# RP2040 register map
Vendor: Raspberry Pi; Series: RP; File version: 0.1
CPU: CM0PLUS r0p1, little endian, MPU, no FPU, VTOR, 2 interrupt priority bits, 32 interrupts
Registers are 32-bit, read-write, reset 0x0 unless marked. A register's access mark holds for its fields unless they carry their own. Offsets are from the block's base; [hi:lo] are bit positions; {n}, {i} and the like mark numbered series; 'fields as' and 'values as' point back to an identical list.

## PWM — Simple PWM
Base 0x40050000
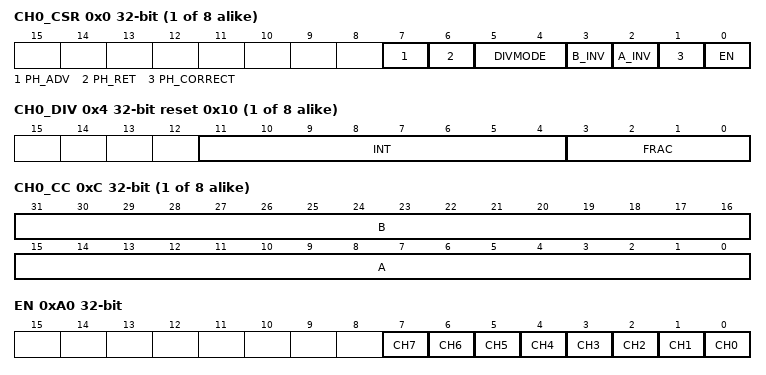
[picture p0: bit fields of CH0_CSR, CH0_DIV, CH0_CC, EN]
{0x0+0x14*i} CH{i}_CSR (i=0..7) — Control and status register
  [7] PH_ADV write-1-clears — Advance the phase of the counter by 1 count, while it is running. Self-clearing. Write a 1, and poll until low. Counter must be running at less than full speed (div_int + div_frac / 16 > 1)
  [6] PH_RET write-1-clears — Retard the phase of the counter by 1 count, while it is running. Self-clearing. Write a 1, and poll until low. Counter must be running.
  [5:4] DIVMODE
    0=div (Free-running counting at rate dictated by fractional divider); 1=level (Fractional divider operation is gated by the PWM B pin.); 2=rise (Counter advances with each rising edge of the PWM B pin.); 3=fall (Counter advances with each falling edge of the PWM B pin.)
  [3] B_INV — Invert output B
  [2] A_INV — Invert output A
  [1] PH_CORRECT — 1: Enable phase-correct modulation. 0: Trailing-edge
  [0] EN — Enable the PWM channel.
{0x4+0x14*i} CH{i}_DIV reset 0x10 (i=0..7) — INT and FRAC form a fixed-point fractional number. Counting rate is system clock frequency divided by this number. Fractional division uses simple 1st-order sigma-delta.
  [11:4] INT, [3:0] FRAC
{0x8+0x14*i} CH{i}_CTR (i=0..7) — Direct access to the PWM counter
  [15:0] CH{i}_CTR
{0xC+0x14*i} CH{i}_CC (i=0..7) — Counter compare values
  [31:16] B, [15:0] A
{0x10+0x14*i} CH{i}_TOP reset 0xFFFF (i=0..7) — Counter wrap value
  [15:0] CH{i}_TOP
0xA0 EN — This register aliases the CSR_EN bits for all channels. Writing to this register allows multiple channels to be enabled or disabled simultaneously, so they can run in perfect sync. For each channel, there is only one physical EN register bit, which can be accessed through here or CHx_CSR.
  [n] CH{n} (n=0..7)
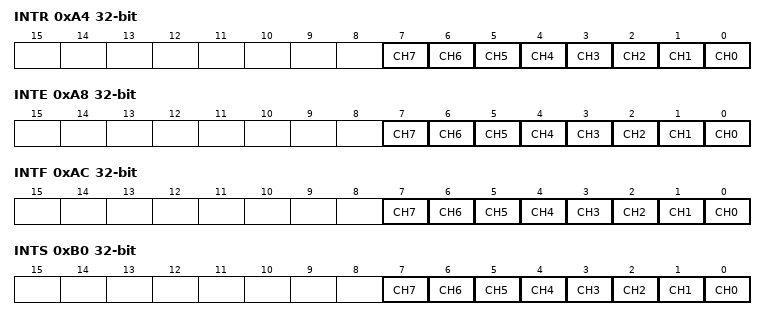
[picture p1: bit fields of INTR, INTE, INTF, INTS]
0xA4 INTR — Raw Interrupts
  [n] CH{n} write-1-clears (n=0..7)
0xA8 INTE — Interrupt Enable
  [n] CH{n} (n=0..7)
0xAC INTF — Interrupt Force
  [n] CH{n} (n=0..7)
0xB0 INTS — Interrupt status after masking & forcing
  [n] CH{n} ro (n=0..7)

## RESETS
Base 0x4000C000
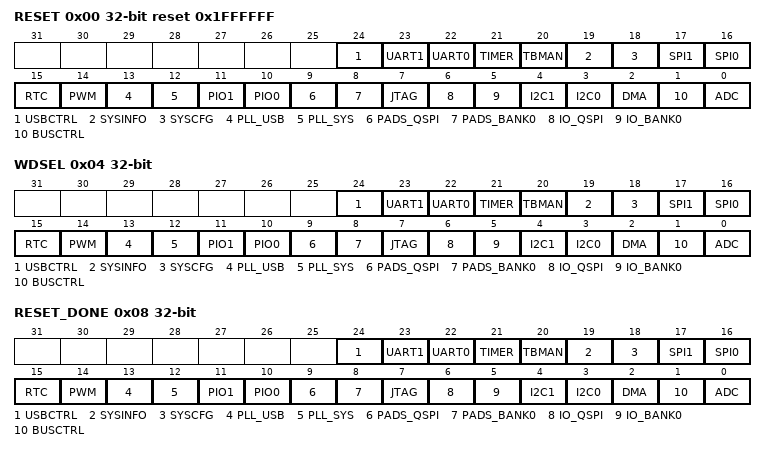
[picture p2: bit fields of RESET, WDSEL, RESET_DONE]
0x00 RESET reset 0x1FFFFFF — Reset control. If a bit is set it means the peripheral is in reset. 0 means the peripheral's reset is deasserted.
  [24] USBCTRL, [23] UART1, [22] UART0, [21] TIMER, [20] TBMAN, [19] SYSINFO, [18] SYSCFG, [17] SPI1, [16] SPI0, [15] RTC, [14] PWM, [13] PLL_USB, [12] PLL_SYS, [11] PIO1, [10] PIO0, [9] PADS_QSPI, [8] PADS_BANK0, [7] JTAG, [6] IO_QSPI, [5] IO_BANK0, [4] I2C1, [3] I2C0, [2] DMA, [1] BUSCTRL, [0] ADC
0x04 WDSEL — Watchdog select. If a bit is set then the watchdog will reset this peripheral when the watchdog fires.
  fields as RESET
0x08 RESET_DONE — Reset done. If a bit is set then a reset done signal has been returned by the peripheral. This indicates that the peripheral's registers are ready to be accessed.
  [24] USBCTRL ro, [23] UART1 ro, [22] UART0 ro, [21] TIMER ro, [20] TBMAN ro, [19] SYSINFO ro, [18] SYSCFG ro, [17] SPI1 ro, [16] SPI0 ro, [15] RTC ro, [14] PWM ro, [13] PLL_USB ro, [12] PLL_SYS ro, [11] PIO1 ro, [10] PIO0 ro, [9] PADS_QSPI ro, [8] PADS_BANK0 ro, [7] JTAG ro, [6] IO_QSPI ro, [5] IO_BANK0 ro, [4] I2C1 ro, [3] I2C0 ro, [2] DMA ro, [1] BUSCTRL ro, [0] ADC ro

## RTC — Register block to control RTC
Base 0x4005C000
0x00 CLKDIV_M1 — Divider minus 1 for the 1 second counter. Safe to change the value when RTC is not enabled.
  [15:0] CLKDIV_M1
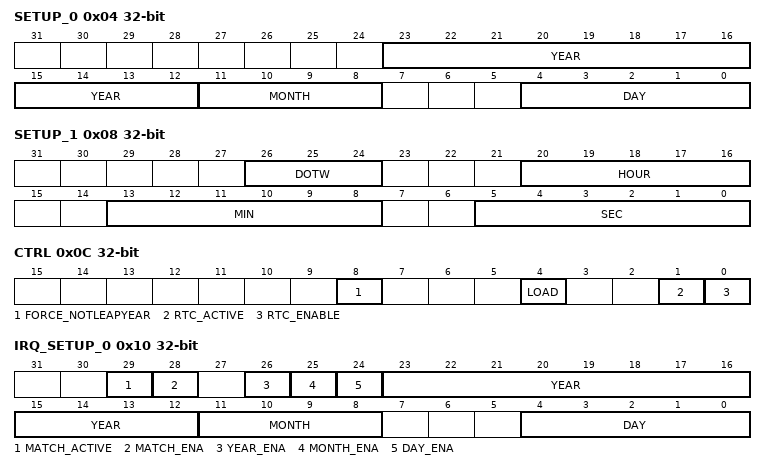
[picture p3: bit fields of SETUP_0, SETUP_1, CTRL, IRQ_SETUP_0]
0x04 SETUP_0 — RTC setup register 0
  [23:12] YEAR
  [11:8] MONTH — Month (1..12)
  [4:0] DAY — Day of the month (1..31)
0x08 SETUP_1 — RTC setup register 1
  [26:24] DOTW — Day of the week: 1-Monday...0-Sunday ISO 8601 mod 7
  [20:16] HOUR — Hours
  [13:8] MIN — Minutes
  [5:0] SEC — Seconds
0x0C CTRL — RTC Control and status
  [8] FORCE_NOTLEAPYEAR — If set, leapyear is forced off. Useful for years divisible by 100 but not by 400
  [4] LOAD write-1-clears — Load RTC
  [1] RTC_ACTIVE ro — RTC enabled (running)
  [0] RTC_ENABLE — Enable RTC
0x10 IRQ_SETUP_0 — Interrupt setup register 0
  [29] MATCH_ACTIVE ro
  [28] MATCH_ENA — Global match enable. Don't change any other value while this one is enabled
  [26] YEAR_ENA — Enable year matching
  [25] MONTH_ENA — Enable month matching
  [24] DAY_ENA — Enable day matching
  [23:12] YEAR
  [11:8] MONTH — Month (1..12)
  [4:0] DAY — Day of the month (1..31)
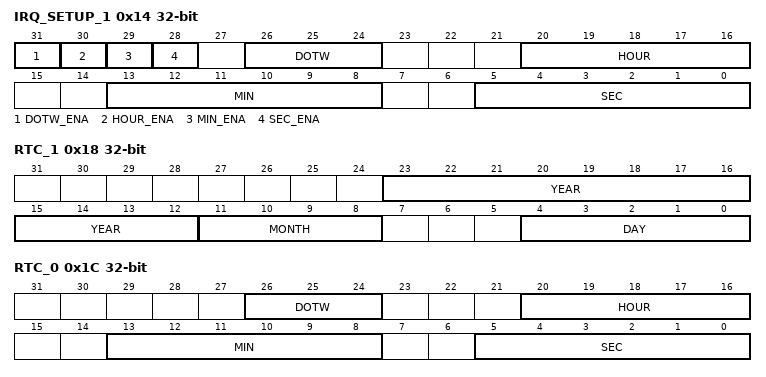
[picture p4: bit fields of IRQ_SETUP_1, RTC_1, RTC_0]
0x14 IRQ_SETUP_1 — Interrupt setup register 1
  [31] DOTW_ENA — Enable day of the week matching
  [30] HOUR_ENA — Enable hour matching
  [29] MIN_ENA — Enable minute matching
  [28] SEC_ENA — Enable second matching
  [26:24] DOTW — Day of the week
  [20:16] HOUR — Hours
  [13:8] MIN — Minutes
  [5:0] SEC — Seconds
0x18 RTC_1 — RTC register 1.
  [23:12] YEAR ro
  [11:8] MONTH ro — Month (1..12)
  [4:0] DAY ro — Day of the month (1..31)
0x1C RTC_0 — RTC register 0 Read this before RTC 1!
  [26:24] DOTW ro read-modifies — Day of the week
  [20:16] HOUR ro read-modifies — Hours
  [13:8] MIN ro read-modifies — Minutes
  [5:0] SEC ro read-modifies — Seconds
0x20 INTR — Raw Interrupts
  [0] RTC ro
0x24 INTE — Interrupt Enable
  [0] RTC
0x28 INTF — Interrupt Force
  [0] RTC
0x2C INTS — Interrupt status after masking & forcing
  [0] RTC ro
